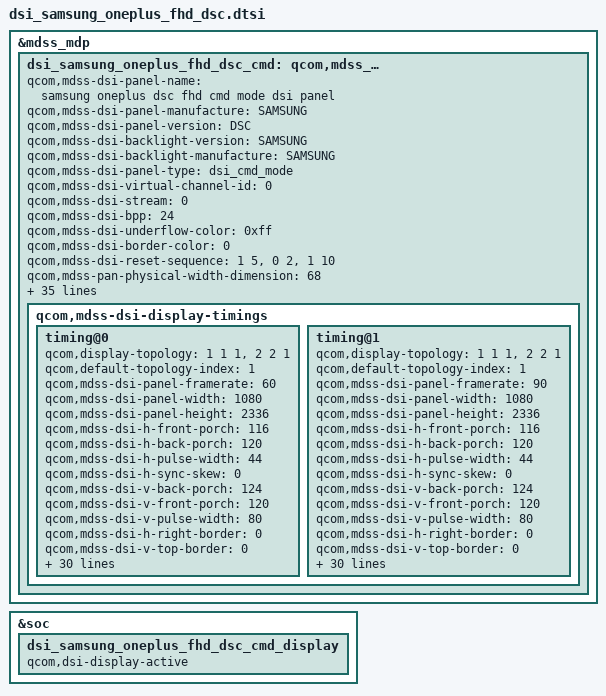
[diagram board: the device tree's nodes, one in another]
/* Copyright (c) 2015-2017, The Linux Foundation. All rights reserved.
 *
 * This program is free software; you can redistribute it and/or modify
 * it under the terms of the GNU General Public License version 2 and
 * only version 2 as published by the Free Software Foundation.
 *
 * This program is distributed in the hope that it will be useful,
 * but WITHOUT ANY WARRANTY; without even the implied warranty of
 * MERCHANTABILITY or FITNESS FOR A PARTICULAR PURPOSE.  See the
 * GNU General Public License for more details.
 */

&mdss_mdp {
	dsi_samsung_oneplus_fhd_dsc_cmd: qcom,mdss_dsi_samsung_oneplus_fhd_dsc_cmd {
		qcom,mdss-dsi-panel-name = "samsung oneplus dsc fhd cmd mode dsi panel";
		qcom,mdss-dsi-panel-manufacture = "SAMSUNG";
		qcom,mdss-dsi-panel-version = "DSC";
		qcom,mdss-dsi-backlight-version = "SAMSUNG";
		qcom,mdss-dsi-backlight-manufacture = "SAMSUNG";
		qcom,mdss-dsi-panel-type = "dsi_cmd_mode";
		qcom,mdss-dsi-virtual-channel-id = <0>;
		qcom,mdss-dsi-stream = <0>;
		qcom,mdss-dsi-bpp = <24>;
		qcom,mdss-dsi-underflow-color = <0xff>;
		qcom,mdss-dsi-border-color = <0>;
		qcom,mdss-dsi-reset-sequence = <1 5>, <0 2>, <1 10>;
		qcom,mdss-pan-physical-width-dimension = <68>;
		qcom,mdss-pan-physical-height-dimension = <145>;
		qcom,mdss-dsi-traffic-mode = "burst_mode";
		qcom,mdss-dsi-bllp-eof-power-mode;
		qcom,mdss-dsi-bllp-power-mode;
		qcom,mdss-dsi-lane-0-state;
		qcom,mdss-dsi-lane-1-state;
		qcom,mdss-dsi-lane-2-state;
		qcom,mdss-dsi-lane-3-state;
		qcom,mdss-dsi-dma-trigger = "trigger_sw";
		qcom,mdss-dsi-mdp-trigger = "none";
		qcom,mdss-dsi-te-pin-select = <1>;
		qcom,mdss-dsi-wr-mem-start = <0x2c>;
		qcom,mdss-dsi-wr-mem-continue = <0x3c>;
		qcom,mdss-dsi-te-dcs-command = <1>;
		qcom,mdss-dsi-te-check-enable;
		qcom,mdss-dsi-te-using-te-pin;
		qcom,mdss-dsi-lp11-init;
	    qcom,mdss-dsi-high-brightness-panel;
		qcom,mdss-dsi-acl-cmd-index = <0>;
		qcom,mdss-dsi-acl-mode-index = <1>;
		qcom,mdss-bl-high2bit;		
		qcom,mdss-dsi-panel-seria-num-year-index = <12>;
		qcom,mdss-dsi-panel-seria-num-mon-index = <12>;
		qcom,mdss-dsi-panel-seria-num-day-index = <13>;
		qcom,mdss-dsi-panel-seria-num-hour-index = <14>;
		qcom,mdss-dsi-panel-seria-num-min-index = <15>;
		qcom,ulps-enabled;
		
		qcom,mdss-dsi-display-timings {
			timing@0{
			qcom,display-topology = <1 1 1>,<2 2 1>;
			qcom,default-topology-index = <1>;
			qcom,mdss-dsi-panel-framerate = <60>;
			qcom,mdss-dsi-panel-width = <1080>;
			qcom,mdss-dsi-panel-height = <2336>;				
			qcom,mdss-dsi-h-front-porch = <116>;
			qcom,mdss-dsi-h-back-porch = <120>;
			qcom,mdss-dsi-h-pulse-width = <44>;
			qcom,mdss-dsi-h-sync-skew = <0>;
			qcom,mdss-dsi-v-back-porch = <124>;
			qcom,mdss-dsi-v-front-porch = <120>;
			qcom,mdss-dsi-v-pulse-width = <80>;
			qcom,mdss-dsi-h-right-border = <0>;
			qcom,mdss-dsi-v-top-border = <0>;
			qcom,mdss-dsi-v-bottom-border = <0>;
			qcom,mdss-dsi-panel-jitter = <0x8 0xa>; 		
			qcom,mdss-dsi-bl-pmic-control-type = "bl_ctrl_dcs";
			qcom,mdss-dsi-panel-clockrate = <1100000000>;
			qcom,mdss-dsi-timing-switch-command = [ 
				29 01 00 00 00 00 03 F0 5A 5A
				07 01 00 00 00 00 01 01
				//29 01 00 00 00 00 02 C3 01
				29 01 00 00 00 00 05 2A 00 00 04 37 	
				29 01 00 00 00 00 05 2B 00 00 09 1F 	
				29 01 00 00 00 00 02 53 20		
				29 01 00 00 00 00 03 F0 A5 A5

			
			];
		qcom,mdss-dsi-panel-phy-timings = [00 16 05 05 20 1f 06 06 03 03 04 00 13 15];
		qcom,mdss-dsi-t-clk-pre = <0x13>;
		qcom,mdss-dsi-t-clk-post = <0x15>;
		qcom,mdss-dsi-on-command = [	
			29 01 00 00 00 00 03 F0 5A 5A		
			07 01 00 00 00 00 01 01
			29 01 00 00 00 00 02 C3 01
			29 01 00 00 00 00 05 2A 00 00 04 37 	
			29 01 00 00 00 00 05 2B 00 00 09 1F 	
			29 01 00 00 00 00 5A 0A 11 00 00 89 30 80 09 20 04 38 00
			49 02 1C 02 1C 02 00 02 0E 00 20
			07 16 00 07 00 0C 01 56 01 65 18
			00 10 F0 03 0C 20 00 06 0B 0B 33
			0E 1C 2A 38 46 54 62 69 70 77 79
			7B 7D 7E 01 02 01 00 09 40 09 BE
			19 FC 19 FA 19 F8 1A 38 1A 78 1A
			B6 2A F6 2B 34 2B 74 3B 74 6B F4 
			00
			39 01 00 00 00 00 02 53 20
			29 01 00 00 00 00 03 F0 A5 A5
			05 01 00 00 0A 00 01 11 	
			15 01 00 00 00 00 02 35 00	
			29 01 00 00 00 00 05 2A 00 00 04 37 	
			29 01 00 00 00 00 05 2B 00 00 09 1F  
			39 01 00 00 00 00 03 F0 5A 5A
			39 01 00 00 00 00 0a B9 01 B0 81 09 00 00 00 11 03
			39 01 00 00 00 00 03 F0 A5 A5					
			29 01 00 00 00 00 03 F0 5A 5A
			15 01 00 00 00 00 02 B0 05
			15 01 00 00 00 00 02 B1 01
			15 01 00 00 00 00 02 B0 02
			15 01 00 00 00 00 02 B5 d3
			29 01 00 00 00 00 03 F0 A5 A5
			39 01 00 00 00 00 02 53 20				
			05 01 00 00 00 00 01 29 	
			];
			qcom,mdss-dsi-off-command = [
			
			/*Display off Delay 20ms*/
			05 01 00 00 14 00 02 28 00
			/*Sleep in*/
			05 01 00 00 00 00 02 10 00
	
			];
			qcom,mdss-dsi-on-command-state = "dsi_lp_mode";
			qcom,mdss-dsi-off-command-state = "dsi_hs_mode";
			qcom,mdss-dsi-timing-switch-command-state = "dsi_lp_mode";
			qcom,mdss-dsi-h-sync-pulse = <0>;					

			qcom,panel-roi-alignment=<540 73 540 73 540 73>;
			qcom,compression-mode = "dsc";
			qcom,lm-split = <540 540>;
			qcom,mdss-dsc-encoders = <2>;
			qcom,mdss-dsc-slice-height = <73>;
			qcom,mdss-dsc-slice-width = <540>;
			qcom,mdss-dsc-slice-per-pkt = <2>;
			qcom,mdss-dsc-bit-per-component = <8>;
			qcom,mdss-dsc-bit-per-pixel = <8>;
			qcom,mdss-dsc-block-prediction-enable;
			};
timing@1{
				qcom,display-topology = <1 1 1>,<2 2 1>;
				qcom,default-topology-index = <1>;
				qcom,mdss-dsi-panel-framerate = <90>;
				qcom,mdss-dsi-panel-width = <1080>;
				qcom,mdss-dsi-panel-height = <2336>;				
				qcom,mdss-dsi-h-front-porch = <116>;
				qcom,mdss-dsi-h-back-porch = <120>;
				qcom,mdss-dsi-h-pulse-width = <44>;
				qcom,mdss-dsi-h-sync-skew = <0>;
				qcom,mdss-dsi-v-back-porch = <124>;
				qcom,mdss-dsi-v-front-porch = <120>;
				qcom,mdss-dsi-v-pulse-width = <80>;
				qcom,mdss-dsi-h-right-border = <0>;
				qcom,mdss-dsi-v-top-border = <0>;
				qcom,mdss-dsi-v-bottom-border = <0>;
				qcom,mdss-dsi-panel-jitter = <0x8 0xa>; 		
				qcom,mdss-dsi-bl-pmic-control-type = "bl_ctrl_dcs";
				qcom,mdss-dsi-panel-clockrate = <1100000000>;
				qcom,mdss-dsi-timing-switch-command = [ 
				29 01 00 00 00 00 03 F0 5A 5A
				07 01 00 00 00 00 01 01
				//29 01 00 00 00 00 02 C3 01
				29 01 00 00 00 00 05 2A 00 00 04 37 	
				29 01 00 00 00 00 05 2B 00 00 09 1F 	
				29 01 00 00 00 00 02 53 30		
				29 01 00 00 00 00 03 F0 A5 A5
				
				];
			qcom,mdss-dsi-panel-phy-timings = [00 1F 08 08 24 22 08 08 05 03 04 00 1A 18];
			qcom,mdss-dsi-t-clk-pre = <0x1A>;
			qcom,mdss-dsi-t-clk-post = <0x18>;
			qcom,mdss-dsi-on-command = [	
				29 01 00 00 00 00 03 F0 5A 5A		
				07 01 00 00 00 00 01 01
				29 01 00 00 00 00 02 C3 01
				29 01 00 00 00 00 05 2A 00 00 04 37 	
				29 01 00 00 00 00 05 2B 00 00 09 1F 	
				29 01 00 00 00 00 5A 0A 11 00 00 89 30 80 09 20 04 38 00
				49 02 1C 02 1C 02 00 02 0E 00 20
				07 16 00 07 00 0C 01 56 01 65 18
				00 10 F0 03 0C 20 00 06 0B 0B 33
				0E 1C 2A 38 46 54 62 69 70 77 79
				7B 7D 7E 01 02 01 00 09 40 09 BE
				19 FC 19 FA 19 F8 1A 38 1A 78 1A
				B6 2A F6 2B 34 2B 74 3B 74 6B F4 
				00
				29 01 00 00 00 00 03 F0 A5 A5
				05 01 00 00 0A 00 01 11 	
				15 01 00 00 00 00 02 35 00	
				29 01 00 00 00 00 05 2A 00 00 04 37 	
				29 01 00 00 00 00 05 2B 00 00 09 1F  
				39 01 00 00 00 00 03 F0 5A 5A
				39 01 00 00 00 00 0a B9 01 B0 81 09 00 00 00 11 03
				39 01 00 00 00 00 03 F0 A5 A5					
				29 01 00 00 00 00 03 F0 5A 5A
				15 01 00 00 00 00 02 B0 05
				15 01 00 00 00 00 02 B1 01
				15 01 00 00 00 00 02 B0 02
				15 01 00 00 00 00 02 B5 d3
				29 01 00 00 00 00 03 F0 A5 A5
				39 01 00 00 00 00 02 53 30				
				05 01 00 00 00 00 01 29 	
				];
				qcom,mdss-dsi-off-command = [
				
				/*Display off Delay 20ms*/
				05 01 00 00 14 00 02 28 00
				/*Sleep in*/
				05 01 00 00 00 00 02 10 00			
				];
				qcom,mdss-dsi-on-command-state = "dsi_lp_mode";
				qcom,mdss-dsi-off-command-state = "dsi_hs_mode";
				qcom,mdss-dsi-timing-switch-command-state = "dsi_lp_mode";
				qcom,mdss-dsi-h-sync-pulse = <0>;		
				qcom,panel-roi-alignment=<540 73 540 73 540 73>;
				qcom,compression-mode = "dsc";
				qcom,lm-split = <540 540>;
				qcom,mdss-dsc-encoders = <2>;
				qcom,mdss-dsc-slice-height = <73>;
				qcom,mdss-dsc-slice-width = <540>;
				qcom,mdss-dsc-slice-per-pkt = <2>;
				qcom,mdss-dsc-bit-per-component = <8>;
				qcom,mdss-dsc-bit-per-pixel = <8>;
				qcom,mdss-dsc-block-prediction-enable;
			
			};

			
		};
	};
};

&dsi_samsung_oneplus_fhd_dsc_cmd {

	qcom,panel-supply-entries = <&dsi_panel_pwr_supply>;
	qcom,mdss-dsi-bl-pmic-control-type = "bl_ctrl_dcs";
	qcom,mdss-dsi-bl-min-level = <1>;
	qcom,mdss-dsi-bl-max-level = <1023>;
	qcom,platform-te-gpio = <&tlmm 8 0>;
	qcom,platform-reset-gpio = <&tlmm 6 0>;
};

&soc {
	dsi_samsung_oneplus_fhd_dsc_cmd_display {
		qcom,dsi-display-active;
	};
};

&dsi_samsung_oneplus_fhd_dsc_cmd{
	qcom,mdss-dsi-display-timings {
		timing@0{
			qcom,mdss-dsi-panel-phy-timings = [00 16 05 05 20 1f 06 06 03 03 04 00 13 15];
			qcom,display-topology = <1 1 1>,<2 2 1>;
			qcom,default-topology-index = <1>;
			};
		timing@1{
			qcom,mdss-dsi-panel-phy-timings = [00 1F 08 08 24 22 08 08 05 03 04 00 1A 18];
			qcom,display-topology = <1 1 1>,<2 2 1>;
			qcom,default-topology-index = <1>;
			};
	};
};

